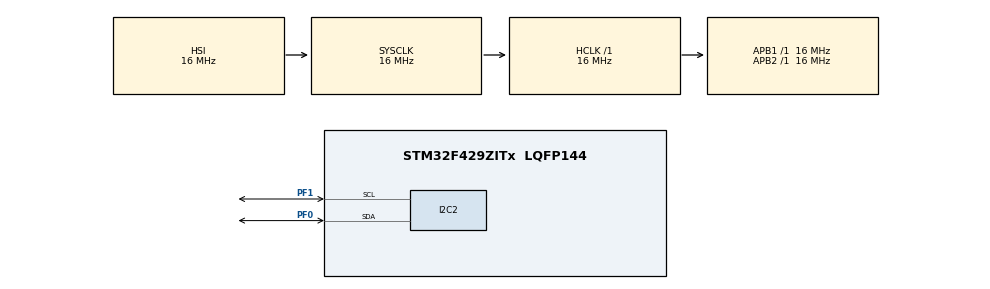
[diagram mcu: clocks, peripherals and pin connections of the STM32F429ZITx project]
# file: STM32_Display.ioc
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I2C2.I2C_Mode=I2C_Fast
Mcu.Family=STM32F4
Mcu.Name=STM32F429ZITx
Mcu.Package=LQFP144
NVIC.PriorityGroup=NVIC_PRIORITYGROUP_4
PA13.Mode=Serial_Wire
PA13.Signal=SYS_JTMS-SWDIO
PA14.Mode=Serial_Wire
PA14.Signal=SYS_JTCK-SWCLK
PF0.Mode=I2C
PF0.Signal=I2C2_SDA
PF1.Mode=I2C
PF1.Signal=I2C2_SCL
PH0/OSC_IN.Mode=HSE-External-Oscillator
PH0/OSC_IN.Signal=RCC_OSC_IN
PH1/OSC_OUT.Mode=HSE-External-Oscillator
PH1/OSC_OUT.Signal=RCC_OSC_OUT
ProjectManager.HeapSize=0x200
ProjectManager.StackSize=0x400
ProjectManager.TargetToolchain=STM32CubeIDE
RCC.48MHZClocksFreq_Value=75000000
RCC.AHBFreq_Value=16000000
RCC.APB1Freq_Value=16000000
RCC.APB2Freq_Value=16000000
RCC.CortexFreq_Value=16000000
RCC.HSE_VALUE=25000000
RCC.HSI_VALUE=16000000
RCC.LSE_VALUE=32768
RCC.PLLSourceVirtual=RCC_PLLSOURCE_HSE
RCC.SYSCLKFreq_VALUE=16000000
RCC.VCOOutputFreq_Value=300000000
board=custom

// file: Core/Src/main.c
/* USER CODE BEGIN Header */
/**
  ******************************************************************************
  * @file           : main.c
  * @brief          : Main program body
  ******************************************************************************
  * @attention
  *
  * <h2><center>&copy; Copyright (c) 2021 STMicroelectronics.
  * All rights reserved.</center></h2>
  *
  * This software component is licensed by ST under BSD 3-Clause license,
  * the "License"; You may not use this file except in compliance with the
  * License. You may obtain a copy of the License at:
  *                        opensource.org/licenses/BSD-3-Clause
  *
  ******************************************************************************
  */
/* USER CODE END Header */
#include "main.h"

/* USER CODE BEGIN Includes */
#include <string.h>
#include <stdio.h>
#include "ssd1306.h"
#include "fonts.h"
#include "test.h"
#include "bitmap.h"
#include "sine_animation.h"

#include "llist.h"
/* USER CODE END Includes */

I2C_HandleTypeDef hi2c2;

void SystemClock_Config(void);
static void MX_GPIO_Init(void);
static void MX_I2C2_Init(void);

int main(void)
{

  /* MCU Configuration--------------------------------------------------------*/

  /* Reset of all peripherals, Initializes the Flash interface and the Systick. */
  HAL_Init();

  /* Configure the system clock */
  SystemClock_Config();

  /* Initialize all configured peripherals */
  MX_GPIO_Init();
  MX_I2C2_Init();
  /* USER CODE BEGIN 2 */

   	  	  	SSD1306_Init (); // initialize the LCD screen display

 //print something on the screen
   	  	  	SSD1306_GotoXY (10,10); 					// goto 10, 10
   	  	  	SSD1306_Puts ("ECE 186B", &Font_11x18, 1); // print ECE 186B & our names
   	  	  	SSD1306_GotoXY (10, 30);
   	  	  	SSD1306_Puts ("Joshua Mendoza", &Font_7x10, 1);
   	  	  	SSD1306_GotoXY (10, 40);
   	  	  	SSD1306_Puts ("Megan Abundo", &Font_7x10, 1);
   	  	  	SSD1306_GotoXY (10, 50);
   	  	  	SSD1306_Puts ("Paris Villarrial", &Font_7x10, 1);
   	  	  	SSD1306_UpdateScreen(); 					// update screen [DISPLAY]

   	  	  	HAL_Delay (1000);							//2 second delay

//   	  	  	SSD1306_Stopscroll(); 						//Stop Scrolling, it will go on forever otherwise
//  	  	  	SSD1306_Clear();

///////Upload Custom Image by using a drawn bitmap//////////////
//   	  	  	SSD1306_DrawBitmap(30,0,FSULogo,128,64,1); //custom bitmap for a custom image
// 	  	  	  	SSD1306_Clear();
//    	  	  	SSD1306_DrawBitmap(0,0,wave1,128,64,1);
//    	  	  	SSD1306_InvertDisplay(1);
//    	  	  	SSD1306_UpdateScreen();

//   	  	  	HAL_Delay (2000);							//2 second delay

 // 	  	  	SSD1306_ScrollLeft(0x00, 0x0f); 			//Scroll entire screen left
 // 	  	  	HAL_Delay (2000); 							//2 second delay

//  	  	  	SSD1306_ScrollRight(0x00, 0x0f); 			//Scroll entire screen right
//  	  	  	HAL_Delay (2000);							//2 second delay

//   	  	  	SSD1306_Scrolldiagright(0x00, 0x0f); 		//Scroll entire screen diagonally right
//	  	  	HAL_Delay (2000); 							//2 second delay

//   	  	  	SSD1306_Scrolldiagleft(0x00, 0x0f); 		//Scroll entire screen diagonally left
//  	  	  	HAL_Delay (2000);							//2 second delay

  //	  		SSD1306_Stopscroll();						//stop scrolling

///////////////////////////////INVERT FUNCTIONS//////////////////////////////////////////////////////////////
   	  		//SSD1306_InvertDisplay(1); 					//Invert the display
   	  		//HAL_Delay (2000);							//2 second delay
   	  		//SSD1306_InvertDisplay(0); 					//normalize display

////////////////////////////////TESTING FUCNTIONS/////////////////////////////////////////////////////////////////

   	  	  	//TestLines(1);
   	  	  	//HAL_Delay(1000);
   	  	  	//TestTriangles(1);
   	  	  	//HAL_Delay(1000);
   	  	  	//TestRectangles(1);
   	  	  	//HAL_Delay(1000);
   	  	  	//TestFilledRectangles(1);
   	  	  	//HAL_Delay(1000);
   	  	  	//TestCircles(6,1);
   	  	  	//HAL_Delay(1000);
   	  	  	//TestFilledCircles(6,1);
   	  	  	//HAL_Delay(1000);

///////////////////////////////////////////////////////////////////////////////////////////

/*
   		  //////////////////////////////////////////////////CUSTOM ANIMATION//////////////////////////////////////
   		  	  	  	  	SSD1306_Clear();
   		     	  	  	SSD1306_DrawBitmap(0,0,wave1,128,64,1);
   		     	  	  	SSD1306_InvertDisplay(1);
   		     	  	  	SSD1306_UpdateScreen();

   		     	  	  	SSD1306_Clear();
   		     	  	  	SSD1306_DrawBitmap(0,0,wave2,128,64,1);
   		     	  	  	SSD1306_InvertDisplay(1);
   		     	  	  	SSD1306_UpdateScreen();

   		     	  	  	SSD1306_Clear();
   		     	  	  	SSD1306_DrawBitmap(0,0,wave3,128,64,1);
   		     	  	  	SSD1306_InvertDisplay(1);
   		     	  	  	SSD1306_UpdateScreen();

   		     	  	  	SSD1306_Clear();
   		     	  	  	SSD1306_DrawBitmap(0,0,wave4,128,64,1);
   		     	  	  	SSD1306_InvertDisplay(1);
   		     	  	  	SSD1306_UpdateScreen();

   		     	  	  	SSD1306_Clear();
   		     	  	  	SSD1306_DrawBitmap(0,0,wave5,128,64,1);
   		     	  	  	SSD1306_InvertDisplay(1);
   		     	  	  	SSD1306_UpdateScreen();

   		     	  	  	SSD1306_Clear();
   		     	  	  	SSD1306_DrawBitmap(0,0,wave6,128,64,1);
   		     	  	  	SSD1306_InvertDisplay(1);
   		     	  	  	SSD1306_UpdateScreen();

   		     	  	  	SSD1306_Clear();
   		     	  	  	SSD1306_DrawBitmap(0,0,wave7,128,64,1);
   		     	  	  	SSD1306_InvertDisplay(1);
   		     	  	  	SSD1306_UpdateScreen();

   		     	  	  	SSD1306_Clear();
   		     	  	  	SSD1306_DrawBitmap(0,0,wave8,128,64,1);
   		     	  	  	SSD1306_InvertDisplay(1);
   		     	  	  	SSD1306_UpdateScreen();

   		     	  	  	SSD1306_Clear();
   		     	  	  	SSD1306_DrawBitmap(0,0,wave9,128,64,1);
   		     	  	  	SSD1306_InvertDisplay(1);
   		     	  	  	SSD1306_UpdateScreen();

   		     	  	  	SSD1306_Clear();
   		     	  	  	SSD1306_DrawBitmap(0,0,wave10,128,64,1);
   		     	  	  	SSD1306_InvertDisplay(1);
   		     	  	  	SSD1306_UpdateScreen();

   		     	  	  	SSD1306_Clear();
   		     	  	  	SSD1306_DrawBitmap(0,0,wave11,128,64,1);
   		     	  	  	SSD1306_InvertDisplay(1);
   		     	  	  	SSD1306_UpdateScreen();

   		     	  	  	SSD1306_Clear();
   		     	  	  	SSD1306_DrawBitmap(0,0,wave12,128,64,1);
   		     	  	  	SSD1306_InvertDisplay(1);
   		     	  	  	SSD1306_UpdateScreen();

   		     	  	  	SSD1306_Clear();
   		     	  	  	SSD1306_DrawBitmap(0,0,wave13,128,64,1);
   		     	  	  	SSD1306_InvertDisplay(1);
   		     	  	  	SSD1306_UpdateScreen();

   		     	  	  	SSD1306_Clear();
   		     	  	  	SSD1306_DrawBitmap(0,0,wave14,128,64,1);
   		     	  	  	SSD1306_InvertDisplay(1);
   		     	  	  	SSD1306_UpdateScreen();

   		     	  	  	SSD1306_Clear();
   		     	  	  	SSD1306_DrawBitmap(0,0,wave15,128,64,1);
   		     	  	  	SSD1306_InvertDisplay(1);
   		     	  	  	SSD1306_UpdateScreen();
//////////////////////////////////////////////////////////////////////////////////
 */

  /* USER CODE END 2 */

  /* Infinite loop */
  while (1)
  {

  }
}

void SystemClock_Config(void)
{
  RCC_OscInitTypeDef RCC_OscInitStruct = {0};
  RCC_ClkInitTypeDef RCC_ClkInitStruct = {0};

  /** Configure the main internal regulator output voltage
  */
  __HAL_RCC_PWR_CLK_ENABLE();
  __HAL_PWR_VOLTAGESCALING_CONFIG(PWR_REGULATOR_VOLTAGE_SCALE3);
  /** Initializes the RCC Oscillators according to the specified parameters
  * in the RCC_OscInitTypeDef structure.
  */
  RCC_OscInitStruct.OscillatorType = RCC_OSCILLATORTYPE_HSI;
  RCC_OscInitStruct.HSIState = RCC_HSI_ON;
  RCC_OscInitStruct.HSICalibrationValue = RCC_HSICALIBRATION_DEFAULT;
  RCC_OscInitStruct.PLL.PLLState = RCC_PLL_NONE;
  if (HAL_RCC_OscConfig(&RCC_OscInitStruct) != HAL_OK)
  {
    Error_Handler();
  }
  /** Initializes the CPU, AHB and APB buses clocks
  */
  RCC_ClkInitStruct.ClockType = RCC_CLOCKTYPE_HCLK|RCC_CLOCKTYPE_SYSCLK
                              |RCC_CLOCKTYPE_PCLK1|RCC_CLOCKTYPE_PCLK2;
  RCC_ClkInitStruct.SYSCLKSource = RCC_SYSCLKSOURCE_HSI;
  RCC_ClkInitStruct.AHBCLKDivider = RCC_SYSCLK_DIV1;
  RCC_ClkInitStruct.APB1CLKDivider = RCC_HCLK_DIV1;
  RCC_ClkInitStruct.APB2CLKDivider = RCC_HCLK_DIV1;

  if (HAL_RCC_ClockConfig(&RCC_ClkInitStruct, FLASH_LATENCY_0) != HAL_OK)
  {
    Error_Handler();
  }
}

static void MX_I2C2_Init(void)
{

  hi2c2.Instance = I2C2;
  hi2c2.Init.ClockSpeed = 400000;
  hi2c2.Init.DutyCycle = I2C_DUTYCYCLE_2;
  hi2c2.Init.OwnAddress1 = 0;
  hi2c2.Init.AddressingMode = I2C_ADDRESSINGMODE_7BIT;
  hi2c2.Init.DualAddressMode = I2C_DUALADDRESS_DISABLE;
  hi2c2.Init.OwnAddress2 = 0;
  hi2c2.Init.GeneralCallMode = I2C_GENERALCALL_DISABLE;
  hi2c2.Init.NoStretchMode = I2C_NOSTRETCH_DISABLE;
  if (HAL_I2C_Init(&hi2c2) != HAL_OK)
  {
    Error_Handler();
  }
  /** Configure Analogue filter
  */
  if (HAL_I2CEx_ConfigAnalogFilter(&hi2c2, I2C_ANALOGFILTER_ENABLE) != HAL_OK)
  {
    Error_Handler();
  }
  /** Configure Digital filter
  */
  if (HAL_I2CEx_ConfigDigitalFilter(&hi2c2, 0) != HAL_OK)
  {
    Error_Handler();
  }

}

static void MX_GPIO_Init(void)
{

  /* GPIO Ports Clock Enable */
  __HAL_RCC_GPIOF_CLK_ENABLE();
  __HAL_RCC_GPIOH_CLK_ENABLE();
  __HAL_RCC_GPIOA_CLK_ENABLE();

}

void Error_Handler(void)
{
  __disable_irq();
  while (1)
  {
  }
}

/************************ (C) COPYRIGHT STMicroelectronics *****END OF FILE****/
